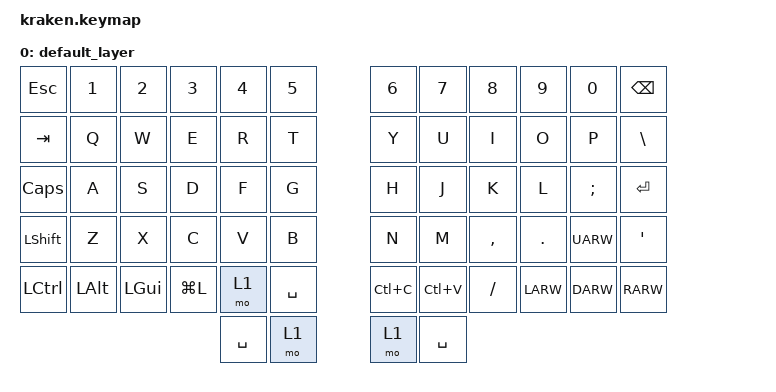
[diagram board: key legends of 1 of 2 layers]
/*
 * Copyright (c) 2020 The ZMK Contributors
 *
 * SPDX-License-Identifier: MIT
 */

#include <behaviors.dtsi>
#include <dt-bindings/zmk/keys.h>
#include <dt-bindings/zmk/bt.h>

/ {
        keymap {
                compatible = "zmk,keymap";

                default_layer {
// ---------------------------------------------------------------------------------
// |  ESC |  1  |  2  |  3  |  4  |  5  |     |  6  |  7  |  8  |  9  |  0  | BKSP |
// |  TAB |  Q  |  W  |  E  |  R  |  T  |     |  Y  |  U  |  I  |  O  |  P  |  \   |
// | CAPS |  A  |  S  |  D  |  F  |  G  |     |  H  |  J  |  K  |  L  |  ;  |  ENT |
// | SHFT |  Z  |  X  |  C  |  V  |  B  |     |  N  |  M  |  ,  |  .  |UARW | APOS |
// | CTRL | ALT |WIND | SLP | SPC | LOW |     | CPY | PST |  /  |LARW |DARW | RARW |
//                          | SPC | LOW |     | LOW | SPC |
                        bindings = <
   &kp ESC    &kp N1    &kp N2    &kp N3        &kp N4     &kp N5               &kp N6     &kp N7    &kp N8     &kp N9    &kp N0    &kp BSPC
   &kp TAB    &kp Q     &kp W     &kp E         &kp R      &kp T                &kp Y      &kp U     &kp I      &kp O     &kp P     &kp BSLH
   &kp CAPS   &kp A     &kp S     &kp D         &kp F      &kp G                &kp H      &kp J     &kp K      &kp L     &kp SEMI  &kp RET
   &kp LSHFT  &kp Z     &kp X     &kp C         &kp V      &kp B                &kp N      &kp M     &kp COMMA  &kp DOT   &kp UARW  &kp APOS
   &kp LCTRL  &kp LALT  &kp LGUI  &kp LG(L)     &mo 1      &kp SPACE            &kp LC(C)  &kp LC(V) &kp SLASH  &kp LARW  &kp DARW  &kp RARW
                                                &kp SPACE  &mo 1                &mo 1      &kp SPACE
                        >;
                };
                lower_layer {
// ------------------------------------------------------------------------------------------------------------
// |       |  BT1  |  BT2  |  BT3  |  BT4  |  BT5  |          |       |       |       |       |       | BTCLR |
// |   F1  |  F2   |   F3  | F4    |  F5   | F6    |          |  F7   |  F8   | F9    | F10   | F11  |  F12  |
// |       |       |       | LPAR  | RPAR  |       |          |       | LBKT  | RBKT  |       |       |       |
// |       |       |       |       |       |       |          |       |       |       |       |       |       |
                        bindings = <
   &trans    &bt BT_SEL 0   &bt BT_SEL 1   &bt BT_SEL 2   &bt BT_SEL 3   &bt BT_SEL 4           &trans    &trans    &trans   &trans   &trans  &bt BT_CLR
   &kp F1    &kp F2         &kp F3         &kp F4         &kp F5         &kp F6                 &kp F7    &kp F8    &kp F9   &kp F10  &kp F11 &kp F12
   &trans    &trans         &trans         &kp LPAR       &kp RPAR       &trans                 &trans    &kp LBKT  &kp RBKT &kp MINUS   &kp EQUAL  &trans
   &trans    &trans         &trans         &trans         &trans         &trans                 &trans    &trans    &trans   &trans   &trans  &trans
                                                          &trans         &trans                 &kp LC(X) &trans
                        >;
                };
        };
};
